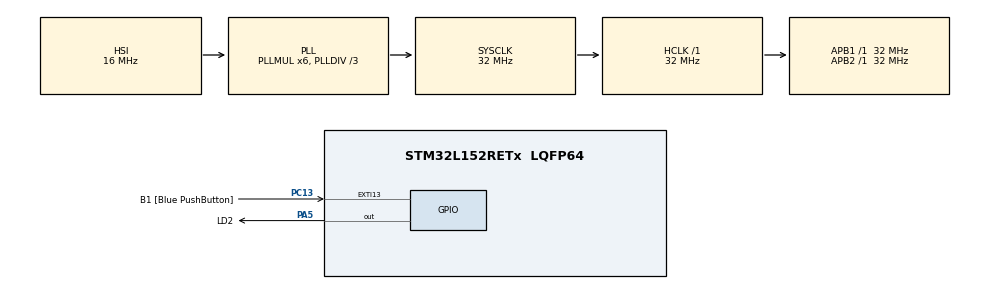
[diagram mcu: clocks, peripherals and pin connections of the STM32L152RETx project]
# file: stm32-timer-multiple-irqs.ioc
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Mcu.Family=STM32L1
Mcu.Name=STM32L152RETx
Mcu.Package=LQFP64
NVIC.PriorityGroup=NVIC_PRIORITYGROUP_0
NVIC.TIM2_IRQn=true\:0\:0\:false\:false\:true\:true\:true\:true
PA13.GPIO_Label=TMS
PA13.Mode=Trace_Asynchronous_SW
PA13.Signal=SYS_JTMS-SWDIO
PA14.GPIO_Label=TCK
PA14.Mode=Trace_Asynchronous_SW
PA14.Signal=SYS_JTCK-SWCLK
PA2.GPIO_Label=USART_TX
PA2.Signal=USART2_TX
PA3.GPIO_Label=USART_RX
PA3.Signal=USART2_RX
PA5.GPIO_Label=LD2
PA5.Signal=GPIO_Output
PB3.GPIO_Label=SWO
PB3.Mode=Trace_Asynchronous_SW
PB3.Signal=SYS_JTDO-TRACESWO
PC13-WKUP2.GPIO_Label=B1 [Blue PushButton]
PC13-WKUP2.Signal=GPXTI13
PC14-OSC32_IN.Mode=LSE-External-Oscillator
PC14-OSC32_IN.Signal=RCC_OSC32_IN
PC15-OSC32_OUT.Mode=LSE-External-Oscillator
PC15-OSC32_OUT.Signal=RCC_OSC32_OUT
PH0-OSC_IN.Mode=HSE-External-Clock-Source
PH0-OSC_IN.Signal=RCC_OSC_IN
PH1-OSC_OUT.Signal=RCC_OSC_OUT
ProjectManager.HeapSize=0x200
ProjectManager.StackSize=0x400
ProjectManager.TargetToolchain=STM32CubeIDE
RCC.48MHZClocksFreq_Value=48000000
RCC.AHBFreq_Value=32000000
RCC.APB1Freq_Value=32000000
RCC.APB1TimFreq_Value=32000000
RCC.APB2Freq_Value=32000000
RCC.APB2TimFreq_Value=32000000
RCC.HCLKFreq_Value=32000000
RCC.HSE_VALUE=8000000
RCC.HSI_VALUE=16000000
RCC.MSI_VALUE=2097000
RCC.PLLDIV=RCC_PLL_DIV3
RCC.PLLMUL=RCC_PLL_MUL6
RCC.RTCClockSelectionVirtual=RCC_RTCCLKSOURCE_LSE
RCC.SYSCLKFreq_VALUE=32000000
RCC.SYSCLKSource=RCC_SYSCLKSOURCE_PLLCLK
RCC.USBOutput=48000000
RCC.VCOOutputFreq_Value=96000000
TIM2.Channel-Output\ Compare1\ No\ Output=TIM_CHANNEL_1
TIM2.Channel-Output\ Compare2\ No\ Output=TIM_CHANNEL_2
TIM2.OCMode_1=TIM_OCMODE_ACTIVE
TIM2.OCMode_2=TIM_OCMODE_ACTIVE
TIM2.OCPolarity_1=TIM_OCPOLARITY_LOW
TIM2.OCPolarity_2=TIM_OCPOLARITY_LOW
TIM2.Period=1000-1
TIM2.Prescaler=32000-1
TIM2.Pulse-Output\ Compare1\ No\ Output=200
TIM2.Pulse-Output\ Compare2\ No\ Output=500
TIM2.TIM_MasterOutputTrigger=TIM_TRGO_UPDATE
VP_TIM2_VS_ClockSourceINT.Mode=Internal
VP_TIM2_VS_no_output1.Mode=Output Compare1 No Output
VP_TIM2_VS_no_output2.Mode=Output Compare2 No Output
board=NUCLEO-L152RE

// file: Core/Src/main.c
/* USER CODE BEGIN Header */
/**
  ******************************************************************************
  * @file           : main.c
  * @brief          : Main program body
  ******************************************************************************
  * @attention
  *
  * Copyright (c) 2023 STMicroelectronics.
  * All rights reserved.
  *
  * This software is licensed under terms that can be found in the LICENSE file
  * in the root directory of this software component.
  * If no LICENSE file comes with this software, it is provided AS-IS.
  *
  ******************************************************************************
  */
/* USER CODE END Header */
#include "main.h"

TIM_HandleTypeDef htim2;

void SystemClock_Config(void);
static void MX_GPIO_Init(void);
static void MX_TIM2_Init(void);

/* USER CODE BEGIN 0 */

uint32_t a=0,b=0;
uint32_t cnt=0;

/* USER CODE END 0 */

int main(void)
{

  /* MCU Configuration--------------------------------------------------------*/

  /* Reset of all peripherals, Initializes the Flash interface and the Systick. */
  HAL_Init();

  /* Configure the system clock */
  SystemClock_Config();

  /* Initialize all configured peripherals */
  MX_GPIO_Init();
  MX_TIM2_Init();
  /* USER CODE BEGIN 2 */

  HAL_TIM_OC_Start_IT(&htim2, TIM_CHANNEL_1);
  HAL_TIM_OC_Start_IT(&htim2, TIM_CHANNEL_2);

  // When starting OC mode, the overflow interrupt is not enabled by default. So wedo it manually
  __HAL_TIM_ENABLE_IT(&htim2, TIM_IT_UPDATE);

  /* USER CODE END 2 */

  /* Infinite loop */
  /* USER CODE BEGIN WHILE */
  while (1)
  {
	  // Some delay. We don't want to call ITM data transfer too often
	  for (int i=0; i<1000; i++)
		  asm("nop");

	  // Read counter to a variable. This operation triggers the ITM data transfer
	  // that you will see on the SWV Data Trace plot
	  cnt = htim2.Instance->CNT;

    /* USER CODE END WHILE */

  }
}

void SystemClock_Config(void)
{
  RCC_OscInitTypeDef RCC_OscInitStruct = {0};
  RCC_ClkInitTypeDef RCC_ClkInitStruct = {0};

  /** Configure the main internal regulator output voltage
  */
  __HAL_PWR_VOLTAGESCALING_CONFIG(PWR_REGULATOR_VOLTAGE_SCALE1);

  /** Initializes the RCC Oscillators according to the specified parameters
  * in the RCC_OscInitTypeDef structure.
  */
  RCC_OscInitStruct.OscillatorType = RCC_OSCILLATORTYPE_HSI;
  RCC_OscInitStruct.HSIState = RCC_HSI_ON;
  RCC_OscInitStruct.HSICalibrationValue = RCC_HSICALIBRATION_DEFAULT;
  RCC_OscInitStruct.PLL.PLLState = RCC_PLL_ON;
  RCC_OscInitStruct.PLL.PLLSource = RCC_PLLSOURCE_HSI;
  RCC_OscInitStruct.PLL.PLLMUL = RCC_PLL_MUL6;
  RCC_OscInitStruct.PLL.PLLDIV = RCC_PLL_DIV3;
  if (HAL_RCC_OscConfig(&RCC_OscInitStruct) != HAL_OK)
  {
    Error_Handler();
  }

  /** Initializes the CPU, AHB and APB buses clocks
  */
  RCC_ClkInitStruct.ClockType = RCC_CLOCKTYPE_HCLK|RCC_CLOCKTYPE_SYSCLK
                              |RCC_CLOCKTYPE_PCLK1|RCC_CLOCKTYPE_PCLK2;
  RCC_ClkInitStruct.SYSCLKSource = RCC_SYSCLKSOURCE_PLLCLK;
  RCC_ClkInitStruct.AHBCLKDivider = RCC_SYSCLK_DIV1;
  RCC_ClkInitStruct.APB1CLKDivider = RCC_HCLK_DIV1;
  RCC_ClkInitStruct.APB2CLKDivider = RCC_HCLK_DIV1;

  if (HAL_RCC_ClockConfig(&RCC_ClkInitStruct, FLASH_LATENCY_1) != HAL_OK)
  {
    Error_Handler();
  }
}

static void MX_TIM2_Init(void)
{

  TIM_ClockConfigTypeDef sClockSourceConfig = {0};
  TIM_MasterConfigTypeDef sMasterConfig = {0};
  TIM_OC_InitTypeDef sConfigOC = {0};

  htim2.Instance = TIM2;
  htim2.Init.Prescaler = 32000-1;
  htim2.Init.CounterMode = TIM_COUNTERMODE_UP;
  htim2.Init.Period = 1000-1;
  htim2.Init.ClockDivision = TIM_CLOCKDIVISION_DIV1;
  htim2.Init.AutoReloadPreload = TIM_AUTORELOAD_PRELOAD_DISABLE;
  if (HAL_TIM_Base_Init(&htim2) != HAL_OK)
  {
    Error_Handler();
  }
  sClockSourceConfig.ClockSource = TIM_CLOCKSOURCE_INTERNAL;
  if (HAL_TIM_ConfigClockSource(&htim2, &sClockSourceConfig) != HAL_OK)
  {
    Error_Handler();
  }
  if (HAL_TIM_OC_Init(&htim2) != HAL_OK)
  {
    Error_Handler();
  }
  sMasterConfig.MasterOutputTrigger = TIM_TRGO_UPDATE;
  sMasterConfig.MasterSlaveMode = TIM_MASTERSLAVEMODE_DISABLE;
  if (HAL_TIMEx_MasterConfigSynchronization(&htim2, &sMasterConfig) != HAL_OK)
  {
    Error_Handler();
  }
  sConfigOC.OCMode = TIM_OCMODE_ACTIVE;
  sConfigOC.Pulse = 200;
  sConfigOC.OCPolarity = TIM_OCPOLARITY_LOW;
  sConfigOC.OCFastMode = TIM_OCFAST_DISABLE;
  if (HAL_TIM_OC_ConfigChannel(&htim2, &sConfigOC, TIM_CHANNEL_1) != HAL_OK)
  {
    Error_Handler();
  }
  sConfigOC.Pulse = 500;
  if (HAL_TIM_OC_ConfigChannel(&htim2, &sConfigOC, TIM_CHANNEL_2) != HAL_OK)
  {
    Error_Handler();
  }

}

static void MX_GPIO_Init(void)
{
  GPIO_InitTypeDef GPIO_InitStruct = {0};

  /* GPIO Ports Clock Enable */
  __HAL_RCC_GPIOC_CLK_ENABLE();
  __HAL_RCC_GPIOH_CLK_ENABLE();
  __HAL_RCC_GPIOA_CLK_ENABLE();
  __HAL_RCC_GPIOB_CLK_ENABLE();

  /*Configure GPIO pin Output Level */
  HAL_GPIO_WritePin(LD2_GPIO_Port, LD2_Pin, GPIO_PIN_RESET);

  /*Configure GPIO pin : B1_Pin */
  GPIO_InitStruct.Pin = B1_Pin;
  GPIO_InitStruct.Mode = GPIO_MODE_IT_RISING;
  GPIO_InitStruct.Pull = GPIO_NOPULL;
  HAL_GPIO_Init(B1_GPIO_Port, &GPIO_InitStruct);

  /*Configure GPIO pins : USART_TX_Pin USART_RX_Pin */
  GPIO_InitStruct.Pin = USART_TX_Pin|USART_RX_Pin;
  GPIO_InitStruct.Mode = GPIO_MODE_AF_PP;
  GPIO_InitStruct.Pull = GPIO_NOPULL;
  GPIO_InitStruct.Speed = GPIO_SPEED_FREQ_VERY_HIGH;
  GPIO_InitStruct.Alternate = GPIO_AF7_USART2;
  HAL_GPIO_Init(GPIOA, &GPIO_InitStruct);

  /*Configure GPIO pin : LD2_Pin */
  GPIO_InitStruct.Pin = LD2_Pin;
  GPIO_InitStruct.Mode = GPIO_MODE_OUTPUT_PP;
  GPIO_InitStruct.Pull = GPIO_NOPULL;
  GPIO_InitStruct.Speed = GPIO_SPEED_FREQ_LOW;
  HAL_GPIO_Init(LD2_GPIO_Port, &GPIO_InitStruct);

}

/* USER CODE BEGIN 4 */

void HAL_TIM_OC_DelayElapsedCallback(TIM_HandleTypeDef *htim) {
	if(htim->Channel == HAL_TIM_ACTIVE_CHANNEL_1){
		HAL_GPIO_WritePin(LD2_GPIO_Port, LD2_Pin, GPIO_PIN_SET);
		a = 1;
	}
	if(htim->Channel == HAL_TIM_ACTIVE_CHANNEL_2){
		HAL_GPIO_WritePin(LD2_GPIO_Port, LD2_Pin, GPIO_PIN_RESET);
		b = 1;
	}

}

void HAL_TIM_PeriodElapsedCallback(TIM_HandleTypeDef *htim) {
	a=0;
	b=0;
}

/* USER CODE END 4 */

void Error_Handler(void)
{
  __disable_irq();
  while (1)
  {
  }
}
